# RT584ZCM33 register map
Series: ARMv8-M Mainline; File version: 1.0
CPU: CM33 r0p0, little endian, MPU, no FPU, VTOR, 3 interrupt priority bits
Registers are 32-bit, read-write, reset 0x0 unless marked. A register's access mark holds for its fields unless they carry their own. Offsets are from the block's base; [hi:lo] are bit positions; 'fields as' and 'values as' point back to an identical list; <NAME> marks a mode.

## I2S0_M_Non-Secure — I2S0_M Non-Secure Register block
Base 0x4002D000
Same registers: I2S0_M_Secure 0x5002D000
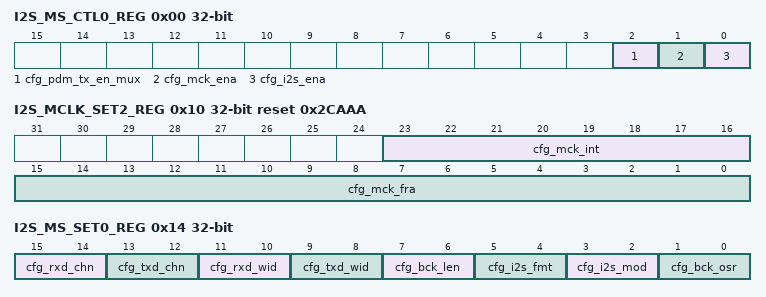
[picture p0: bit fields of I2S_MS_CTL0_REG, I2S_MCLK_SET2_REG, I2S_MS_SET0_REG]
0x00 I2S_MS_CTL0_REG — i2s ms ctl0
  [2] cfg_pdm_tx_en_mux — PDM tx en mux 0: I2S tx data from dma 1: I2S tx data from pdm
    0=B_2_ITEM0 (I2S tx data from dma); 1=B_2_ITEM1 (I2S tx data from pdm)
  [1] cfg_mck_ena — Enable MCLK 0: disable 1: enable
    0=B_1_ITEM0 (disable); 1=B_1_ITEM1 (enable)
  [0] cfg_i2s_ena — Enable I2S 0: disable 1: enable
    0=B_0_ITEM0 (disable); 1=B_0_ITEM1 (enable)
0x04 I2S_MS_CTL1_REG wo — i2s ms ctl1
  [0] cfg_i2s_rst — Reset I2S 1: reset
    0=B_0 (Reset I2S 1: reset)
0x08 I2S_MCLK_SET0_REG — i2s mclk set0
  [2:0] cfg_mck_isel — Internal MCLK rate selection 0: average 12.288M when PLL is 32M 1: average 8.192M when PLL is 32M 2: average 12.288M when PLL is 48M 3: average 8.192M when PLL is 48M 4: average 24.576M when PLL is 64M 5: average 16.384M when PLL is 64M otherwise: MCLK divider value is derived from cfg_mck_int and cfg_mck_frac
    0=B_0_to_2 (Internal MCLK rate selection 0: average 12.288M when PLL is 32M 1: average 8.192M when PLL is 32M 2: average 12.288M when PLL is 48M 3: average 8.192M when PLL is 48M 4: average 24.576M when PLL is 64M 5: average 16.384M when PLL is 64M otherwise: MCLK divider value is derived from cfg_mck_int and cfg_mck_frac)
0x0C I2S_MCLK_SET1_REG — i2s mclk set1
  [3:0] cfg_mck_div — Output MCLK divider 0: internal MCLK divided by 1 1: internal MCLK divided by 2 2: internal MCLK divided by 4 3: internal MCLK divided by 8 4: internal MCLK divided by 16 5: internal MCLK divided by 32 others: internal MCLK divided by 32
    0=B_0_to_3 (Output MCLK divider 0: internal MCLK divided by 1 1: internal MCLK divided by 2 2: internal MCLK divided by 4 3: internal MCLK divided by 8 4: internal MCLK divided by 16 5: internal MCLK divided by 32 others: internal MCLK divided by 32)
0x10 I2S_MCLK_SET2_REG reset 0x2CAAA — i2s mclk set2
  [23:16] cfg_mck_int — MCLK divider interger value
    0=B_16_to_23 (MCLK divider interger value)
  [15:0] cfg_mck_fra — MCLK divider fractional value
0x14 I2S_MS_SET0_REG — i2s ms set0
  [15:14] cfg_rxd_chn — Rx sample format in xdma 0: stereo, L/R 1: mono, L 2: mono, R 3: reserved
    0=B_14_to_15_ITEM0 (stereo, L/R); 1=B_14_to_15_ITEM1 (mono, L); 2=B_14_to_15_ITEM2 (mono, R); 3=B_14_to_15_ITEM3 (Not Used)
  [13:12] cfg_txd_chn — Tx sample format in xdma 0: stereo, L/R 1: mono, L 2: mono, R 3: reserved
    0=B_12_to_13_ITEM0 (stereo, L/R); 1=B_12_to_13_ITEM1 (mono, L); 2=B_12_to_13_ITEM2 (mono, R); 3=B_12_to_13_ITEM3 (Not Used)
  [11:10] cfg_rxd_wid — Sample width for I2S received sample 0: 16-bit 1: 24-bit 2: 32-bit 3: 32-bit
    0=B_10_to_11_ITEM0 (16-bit); 1=B_10_to_11_ITEM1 (24-bit); 2=B_10_to_11_ITEM2 (32-bit); 3=B_10_to_11_ITEM3 (32-bit)
  [9:8] cfg_txd_wid — Sample width for I2S transmited sample 0: 16-bit 1: 24-bit 2: 32-bit 3: 32-bit
    0=B_8_to_9_ITEM0 (16-bit); 1=B_8_to_9_ITEM1 (24-bit); 2=B_8_to_9_ITEM2 (32-bit); 3=B_8_to_9_ITEM3 (32-bit)
  [7:6] cfg_bck_len — Bit Length of BCLK per channel 0: 16 1: 24 (proprietary I2S) 2: 32 3: 32
    0=B_6_to_7_ITEM0 (16); 1=B_6_to_7_ITEM1 (24 (proprietary I2S)); 2=B_6_to_7_ITEM2 (32); 3=B_6_to_7_ITEM3 (32)
  [5:4] cfg_i2s_fmt — I2S format 0: LJ mode 1: RJ mode 2: I2S mode 3: I2S mode
    0=B_4_to_5_ITEM0 (LJ mode); 1=B_4_to_5_ITEM1 (RJ mode); 2=B_4_to_5_ITEM2 (I2S mode); 3=B_4_to_5_ITEM3 (I2S mode)
  [3:2] cfg_i2s_mod — I2S tranceiver mode 0: TxRx 1: Tx only 2: Rx only 3: TxRx
    0=B_2_to_3_ITEM0 (TxRx); 1=B_2_to_3_ITEM1 (Tx only); 2=B_2_to_3_ITEM2 (Rx only); 3=B_2_to_3_ITEM3 (TxRx)
  [1:0] cfg_bck_osr — Ratio of MCLK and BCLK 0: 2 1: 4 2: 8 3: 8
    0=B_0_to_1_ITEM0 (2); 1=B_0_to_1_ITEM1 (4); 2=B_0_to_1_ITEM2 (8); 3=B_0_to_1_ITEM3 (8)
0x40 I2S_RDMA_CTL0_REG wo — i2s rdma ctl0
  [3:0] cfg_i2s_rdma_ctl0 — Write 1 to bit 0 to start xdma for memory read access. Other bits are reserved.
    0=B_0_to_3 (Write 1 to bit 0 to start xdma for memory read access. Other bits are reserved.)
0x44 I2S_RDMA_CTL1_REG wo — i2s rdma ctl1
  [0] cfg_i2s_rdma_ctl1 — Write 1 to reset xdma read control.
    0=B_0 (Write 1 to reset xdma read control.)
0x48 I2S_RDMA_SET0_REG — [15:0] Segment size, 4-byte aligned 0: Illegal value Others: 1 to 65535 (Block size < Segment size) [31:16] Block size, 4-byte aligned 0: Single-shot mode Others: 1 to 65535 (Block size < Segment size)
0x4C I2S_RDMA_SET1_REG — Start address point, 4-byte aligned The 2-LSB bit will be ignored
0x50 I2S_RDMA_SET2_REG — i2s rdma set2
  [7:0] cfg_i2s_rdma_set2 — [0] Set initial address 0: when xdma start, initial address is loaded from ptr 1: when xdma reset, initial address is loaded from ptr [3:1] Reserved [5:4] DMA data format 0: word, 4-bytes aligned 1: halfword, 2-bytes aligned 2/3: 1-byte aligned [7:6] Reserved
    0=B_0_to_7 ([0] Set initial address 0: when xdma start, initial address is loaded from ptr 1: when xdma reset, initial address is loaded from ptr [3:1] Reserved [5:4] DMA data format 0: word, 4-bytes aligned 1: halfword, 2-bytes aligned 2/3: 1-byte aligned [7:6] Reserved)
0x58 I2S_RDMA_R0_REG ro — Status of xdma next pointer address
0x5C I2S_RDMA_R1_REG ro — [0] xdma interrupt status [1] xdma error interrupt status [2] OR(xdma interrupt status, xdma error interrupt status) [9:8] xdma counter status, used for ping-pong buffer to check buffer status [16] xdma enable [17] xdma_done [19:18] xdma_status
0x60 I2S_WDMA_CTL0_REG wo — i2s wdma ctl0
  [3:0] cfg_i2s_wdma_ctl0 — Write 1 to bit 0 to start xdma for memory write access. Other bits are reserved.
    0=B_0_to_3 (Write 1 to bit 0 to start xdma for memory write access. Other bits are reserved.)
0x64 I2S_WDMA_CTL1_REG wo — i2s wdma ctl1
  [0] cfg_i2s_wdma_ctl1 — Write 1 to reset xdma write control.
    0=B_0 (Write 1 to reset xdma write control.)
0x68 I2S_WDMA_SET0_REG — [15:0] Segment size, 4-byte aligned 0: Illegal value Others: 1 to 65535 (Block size < Segment size) [31:16] Block size, 4-byte aligned 0: Single-shot mode Others: 1 to 65535 (Block size < Segment size)
0x6C I2S_WDMA_SET1_REG — Start point address, 4-byte aligned The 2-LSB bit will be ignored
0x70 I2S_WDMA_SET2_REG — i2s wdma set2
  [7:0] cfg_i2s_wdma_set2 — [0] Set initial address 0: when xdma start, initial address is loaded from ptr 1: when xdma reset, initial address is loaded from ptr [3:1] Reserved [5:4] DMA data format 0: word, 4-bytes aligned 1: halfword, 2-bytes aligned 2/3: 1-byte aligned [7:6] Reserved
    values as I2S_RDMA_SET2_REG.cfg_i2s_rdma_set2
0x78 I2S_WDMA_R0_REG ro — Status of xdma next pointer address
0x7C I2S_WDMA_R1_REG ro — [0] xdma interrupt status [1] xdma error interrupt status [2] OR(xdma interrupt status, xdma error interrupt status) [9:8] xdma counter status, used for ping-pong buffer to check buffer status [16] xdma enable [17] xdma_done [19:18] xdma_status
0xA0 I2S_INT_CLEAR_REG wo — i2s int clear
  [3:0] cfg_i2s_int_clear — Write 1 to the specific bit to clear the corresponding interrupt. bit 0: I2S_RDMA interrpt bit 1: I2S_RDMA error interrupt bit 2: I2S_WDMA interrpt bit 3: I2S_WDMA error interrupt
    0=B_0_to_3 (Write 1 to the specific bit to clear the corresponding interrupt. bit 0: I2S_RDMA interrpt bit 1: I2S_RDMA error interrupt bit 2: I2S_WDMA interrpt bit 3: I2S_WDMA error interrupt)
0xA4 I2S_INT_MASK_REG reset 0xA — i2s int mask
  [3:0] cfg_i2s_int_mask — Set the specific bit to high to mask the corresponding interrupt. bit 0: I2S_RDMA interrpt bit 1: I2S_RDMA error interrupt bit 2: I2S_WDMA interrpt bit 3: I2S_WDMA error interrupt
    0=B_0_to_3 (Set the specific bit to high to mask the corresponding interrupt. bit 0: I2S_RDMA interrpt bit 1: I2S_RDMA error interrupt bit 2: I2S_WDMA interrpt bit 3: I2S_WDMA error interrupt)
0xA8 I2S_INT_STATUS_REG ro — i2s int status
  [3:0] cfg_i2s_int_status — Interrupt status. bit 0: I2S_RDMA interrpt bit 1: I2S_RDMA error interrupt bit 2: I2S_WDMA interrpt bit 3: I2S_WDMA error interrupt
    0=B_0_to_3 (Interrupt status. bit 0: I2S_RDMA interrpt bit 1: I2S_RDMA error interrupt bit 2: I2S_WDMA interrpt bit 3: I2S_WDMA error interrupt)
